# APM32F103xx register map
File version: 1.0
CPU: CM3 r2p1, little endian, no MPU, no FPU, 4 interrupt priority bits
Registers are 32-bit, read-write, reset 0x0 unless marked. A register's access mark holds for its fields unless they carry their own. Offsets are from the block's base; [hi:lo] are bit positions; {n}, {i} and the like mark numbered series.

## RCM — Reset and clock management unit
Base 0x40021000
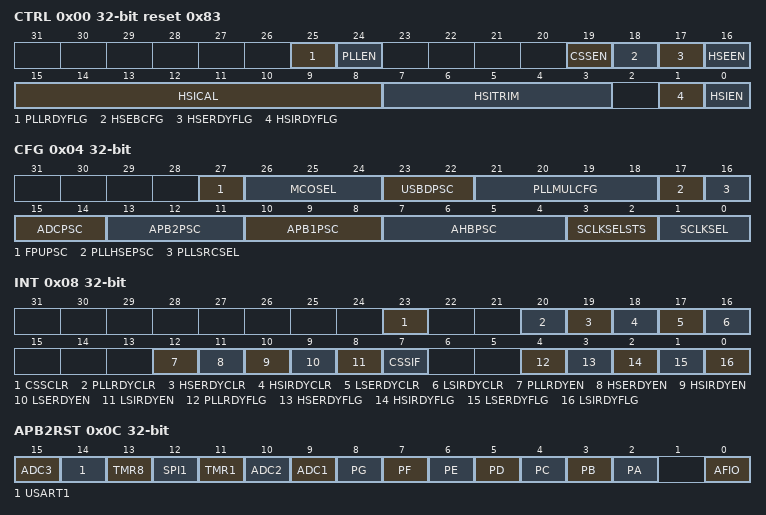
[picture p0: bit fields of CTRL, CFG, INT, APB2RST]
0x00 CTRL access per field reset 0x83 — Clock control register (RCM_CTRL)
  [25] PLLRDYFLG ro — PLL clock ready flag
  [24] PLLEN rw — PLL enable
  [19] CSSEN rw — Clock Security System enable
  [18] HSEBCFG rw — External High Speed clock Bypass
  [17] HSERDYFLG ro — External High Speed clock ready flag
  [16] HSEEN rw — External High Speed clock enable
  [15:8] HSICAL ro — Internal High Speed clock Calibration
  [7:3] HSITRIM rw — Internal High Speed clock trimming
  [1] HSIRDYFLG ro — Internal High Speed clock ready flag
  [0] HSIEN rw — Internal High Speed clock enable
0x04 CFG access per field — Clock configuration register (RCM_CFGR)
  [27] FPUPSC rw — FPU Clock Prescaler Factor Configure
  [26:24] MCOSEL rw — Microcontroller clock output
  [23:22] USBDPSC rw — USB OTG FS prescaler
  [21:18] PLLMULCFG rw — PLL Multiplication Factor
  [17] PLLHSEPSC rw — HSE divider for PLL entry
  [16] PLLSRCSEL rw — PLL entry clock source
  [15:14] ADCPSC rw — ADC prescaler
  [13:11] APB2PSC rw — APB High speed prescaler (APB2)
  [10:8] APB1PSC rw — APB Low speed prescaler (APB1)
  [7:4] AHBPSC rw — AHB prescaler
  [3:2] SCLKSELSTS ro — System Clock Switch Status
  [1:0] SCLKSEL rw — System clock Switch
0x08 INT access per field — Clock interrupt control register (RCM_INT)
  [23] CSSCLR wo — Clock security system interrupt clear
  [20] PLLRDYCLR wo — PLL Ready Interrupt Clear
  [19] HSERDYCLR wo — HSE Ready Interrupt Clear
  [18] HSIRDYCLR wo — HSI Ready Interrupt Clear
  [17] LSERDYCLR wo — LSE Ready Interrupt Clear
  [16] LSIRDYCLR wo — LSI Ready Interrupt Clear
  [12] PLLRDYEN rw — PLL Ready Interrupt Enable
  [11] HSERDYEN rw — HSE Ready Interrupt Enable
  [10] HSIRDYEN rw — HSI Ready Interrupt Enable
  [9] LSERDYEN rw — LSE Ready Interrupt Enable
  [8] LSIRDYEN rw — LSI Ready Interrupt Enable
  [7] CSSIF ro — Clock Security System Interrupt flag
  [4] PLLRDYFLG ro — PLL Ready Interrupt flag
  [3] HSERDYFLG ro — HSE Ready Interrupt flag
  [2] HSIRDYFLG ro — HSI Ready Interrupt flag
  [1] LSERDYFLG ro — LSE Ready Interrupt flag
  [0] LSIRDYFLG ro — LSI Ready Interrupt flag
0x0C APB2RST — APB2 peripheral reset register (RCM_APB2RST)
  [15] ADC3 — ADC3 reset
  [14] USART1 — USART1 reset
  [13] TMR8 — TMR8 timer reset
  [12] SPI1 — SPI 1 reset
  [11] TMR1 — TMR1 timer reset
  [10] ADC2 — ADC 2 interface reset
  [9] ADC1 — ADC 1 interface reset
  [8] PG — IO port G reset
  [7] PF — IO port F reset
  [6] PE — IO port E reset
  [5] PD — IO port D reset
  [4] PC — IO port C reset
  [3] PB — IO port B reset
  [2] PA — IO port A reset
  [0] AFIO — Alternate function I/O reset
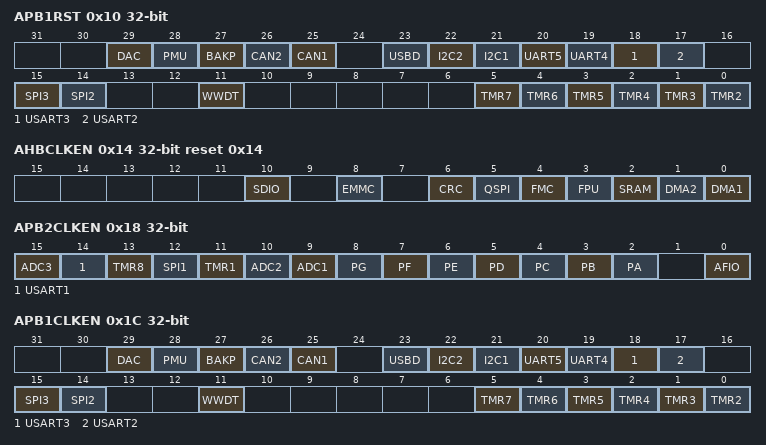
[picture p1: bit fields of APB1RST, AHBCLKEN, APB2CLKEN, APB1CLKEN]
0x10 APB1RST — APB1 peripheral reset register (RCM_APB1RST)
  [29] DAC — DAC interface reset
  [28] PMU — Power interface reset
  [27] BAKP — Bakr interface reset
  [26] CAN2 — CAN2 reset
  [25] CAN1 — CAN1 reset
  [23] USBD — USB reset
  [22] I2C2 — I2C2 reset
  [21] I2C1 — I2C1 reset
  [20] UART5 — UART 5 reset
  [19] UART4 — UART 4 reset
  [18] USART3 — USART 3 reset
  [17] USART2 — USART 2 reset
  [15] SPI3 — SPI3 reset
  [14] SPI2 — SPI2 reset
  [11] WWDT — Window watchdog reset
  [n-2] TMR{n} (n=2..7) — Timer {n} reset
0x14 AHBCLKEN reset 0x14 — AHB clock enable register (RCM_AHBCLKEN)
  [10] SDIO — SDIO clock enable
  [8] EMMC — EMMC clock enable
  [6] CRC — CRC clock enable
  [5] QSPI — QSPI clock enable
  [4] FMC — FMC clock enable
  [3] FPU — FPU clock Enable
  [2] SRAM — SRAM interface clock enable
  [1] DMA2 — DMA2 clock enable
  [0] DMA1 — DMA1 clock enable
0x18 APB2CLKEN — APB2 clock enable register (RCM_APB2CLKEN)
  [15] ADC3 — ADC3 interface clock enable
  [14] USART1 — USART1 clock enable
  [13] TMR8 — TMR8 Timer clock enable
  [12] SPI1 — SPI 1 clock enable
  [11] TMR1 — TMR1 Timer clock enable
  [10] ADC2 — ADC 2 interface clock enable
  [9] ADC1 — ADC 1 interface clock enable
  [8] PG — I/O port G clock enable
  [7] PF — I/O port F clock enable
  [6] PE — I/O port E clock enable
  [5] PD — I/O port D clock enable
  [4] PC — I/O port C clock enable
  [3] PB — I/O port B clock enable
  [2] PA — I/O port A clock enable
  [0] AFIO — Alternate function I/O clock enable
0x1C APB1CLKEN — APB1 clock enable register (RCM_APB1CLKEN)
  [29] DAC — DAC interface clock enable
  [28] PMU — Power interface clock enable
  [27] BAKP — Bakr interface clock enable
  [26] CAN2 — CAN2 clock enable
  [25] CAN1 — CAN1 clock enable
  [23] USBD — USB clock enable
  [22] I2C2 — I2C 2 clock enable
  [21] I2C1 — I2C 1 clock enable
  [20] UART5 — UART 5 clock enable
  [19] UART4 — UART 4 clock enable
  [18] USART3 — USART 3 clock enable
  [17] USART2 — USART 2 clock enable
  [15] SPI3 — SPI 3 clock enable
  [14] SPI2 — SPI 2 clock enable
  [11] WWDT — Window watchdog clock enable
  [n-2] TMR{n} (n=2..7) — Timer {n} clock enable
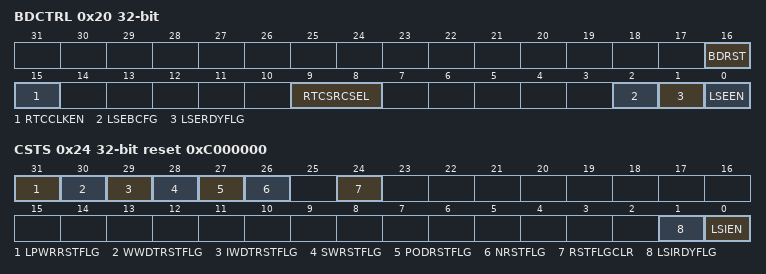
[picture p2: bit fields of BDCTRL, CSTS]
0x20 BDCTRL access per field — Bakr domain control register (RCM_BDCTRL)
  [16] BDRST rw — Bakr domain software reset
  [15] RTCCLKEN rw — RTC clock enable
  [9:8] RTCSRCSEL rw — RTC clock source selection
  [2] LSEBCFG rw — External Low Speed oscillator bypass
  [1] LSERDYFLG ro — External Low Speed oscillator ready
  [0] LSEEN rw — External Low Speed oscillator enable
0x24 CSTS access per field reset 0xC000000 — Control/status register (RCM_CSTS)
  [31] LPWRRSTFLG rw — Low-power reset flag
  [30] WWDTRSTFLG rw — Window watchdog reset flag
  [29] IWDTRSTFLG rw — Independent watchdog reset flag
  [28] SWRSTFLG rw — Software reset flag
  [27] PODRSTFLG rw — POR/PDR reset flag
  [26] NRSTFLG rw — PIN reset flag
  [24] RSTFLGCLR rw — Remove reset flag
  [1] LSIRDYFLG ro — Internal low speed oscillator ready
  [0] LSIEN rw — Internal low speed oscillator enable
